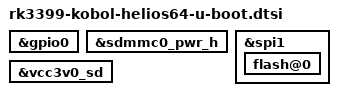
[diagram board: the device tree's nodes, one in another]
// SPDX-License-Identifier: GPL-2.0+
/*
 * Copyright (c) 2020 Aditya Prayoga (aditya@kobol.io)
 */

#include "rk3399-u-boot.dtsi"
#include "rk3399-sdram-lpddr4-100.dtsi"

&gpio0 {
	bootph-pre-ram;
};

&sdmmc0_pwr_h {
	bootph-pre-ram;
};

&spi1 {
	flash@0 {
		bootph-pre-ram;
		bootph-some-ram;
	};
};

&vcc3v0_sd {
	bootph-pre-ram;
};
